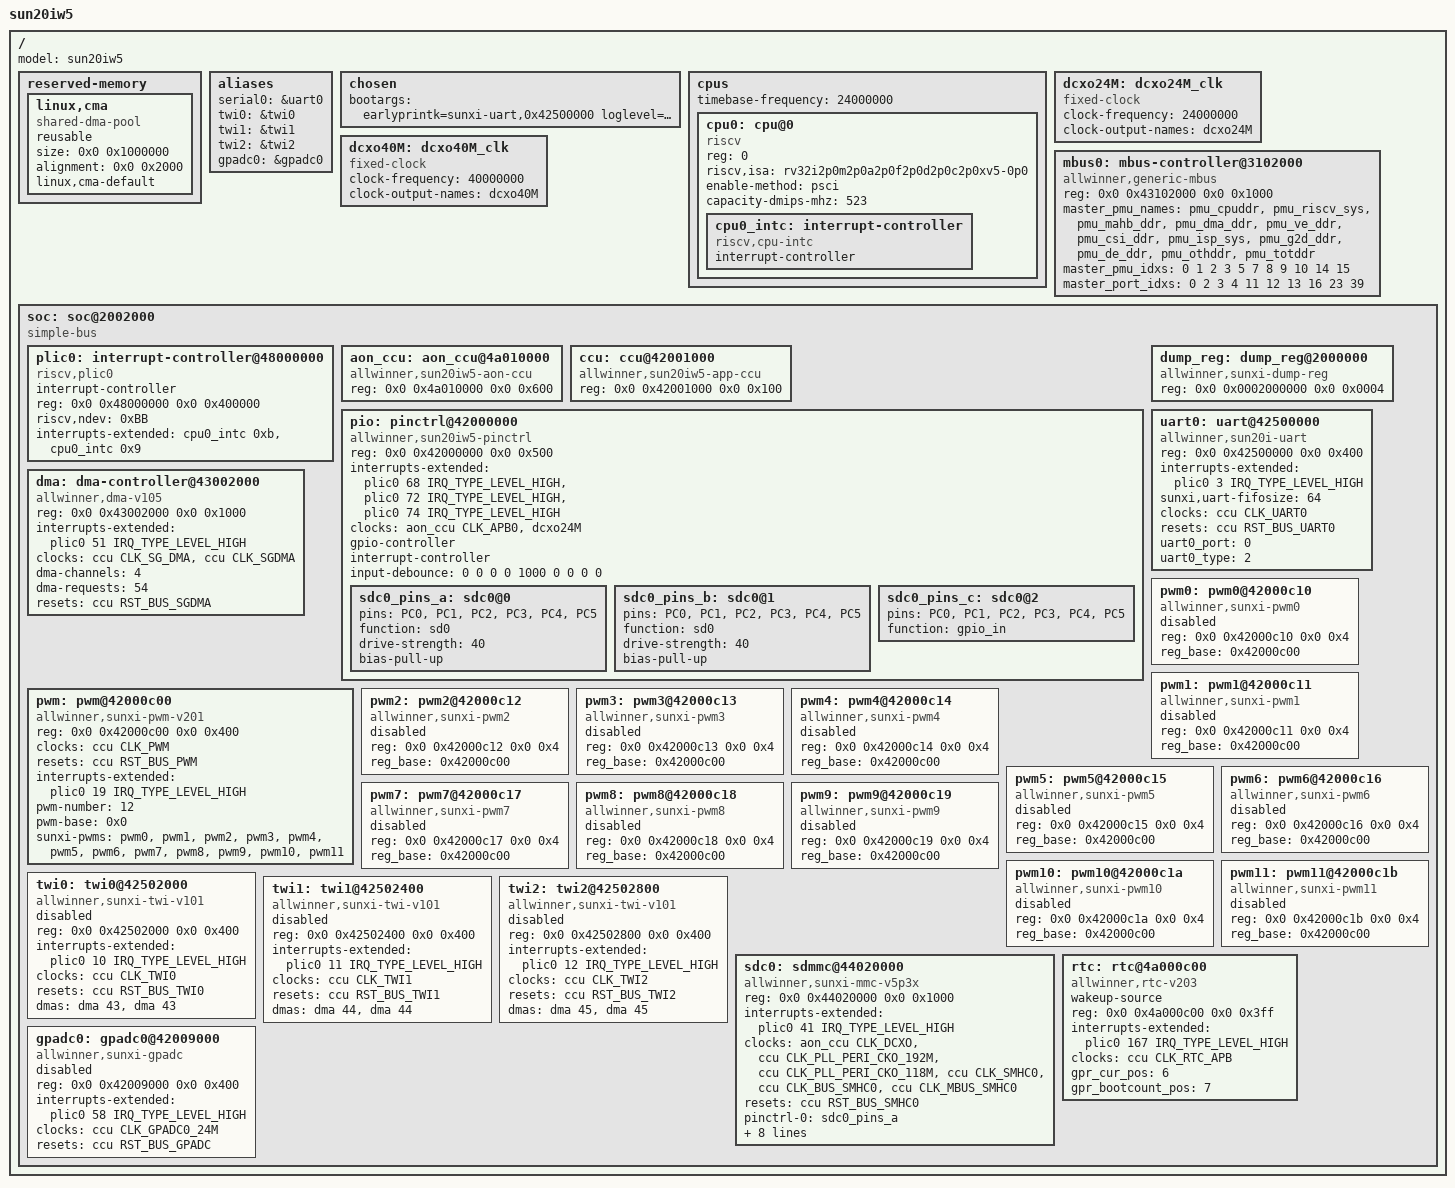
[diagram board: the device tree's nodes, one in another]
// SPDX-License-Identifier: (GPL-2.0+ or MIT)
/*
 * Copyright (C) 2023 rengaomin@allwinnertech.com
 */

/memreserve/ 0x84000000 0x100000; /* opensbi */

#include <dt-bindings/gpio/gpio.h>
#include <dt-bindings/gpio/sun4i-gpio.h>
#include <dt-bindings/thermal/thermal.h>
#include <dt-bindings/interrupt-controller/irq.h>
#include <dt-bindings/clock/sun20iw5-aon-ccu.h>
#include <dt-bindings/clock/sun20iw5-app-ccu.h>
#include <dt-bindings/reset/sun20iw5-app-ccu.h>

/ {
	model = "sun20iw5";
	#address-cells = <2>;
	#size-cells = <2>;

	reserved-memory {
		#address-cells = <2>;
		#size-cells = <2>;
		ranges;

		/* global autoconfigured region for contiguous allocations */
		linux,cma {
			compatible = "shared-dma-pool";
			reusable;
			size = <0x0 0x1000000>;
			alignment = <0x0 0x2000>;
			linux,cma-default;
		};

	};

	aliases {
		serial0 = &uart0;
		twi0 = &twi0;
		twi1 = &twi1;
		twi2 = &twi2;
		gpadc0 = &gpadc0;
	};

	chosen {
		bootargs = "earlyprintk=sunxi-uart,0x42500000 loglevel=8 initcall_debug=1 console=ttyAS0 init=/init";
	};

	cpus {
		#address-cells = <1>;
		#size-cells = <0>;
		timebase-frequency = <24000000>;

		cpu0: cpu@0 {
			device_type = "cpu";
			compatible = "riscv";
			reg = <0>;
			status = "okay";
			riscv,isa = "rv32i2p0m2p0a2p0f2p0d2p0c2p0xv5-0p0";
			enable-method = "psci";
			capacity-dmips-mhz = <523>;

			cpu0_intc: interrupt-controller {
				#interrupt-cells = <0x1>;
				interrupt-controller;
				compatible = "riscv,cpu-intc";
			};
		};
	};

	dcxo24M: dcxo24M_clk {
		#clock-cells = <0>;
		compatible = "fixed-clock";
		clock-frequency = <24000000>;
		clock-output-names = "dcxo24M";
	};

	dcxo40M: dcxo40M_clk {
		#clock-cells = <0>;
		compatible = "fixed-clock";
		clock-frequency = <40000000>;
		clock-output-names = "dcxo40M";
	};

	mbus0: mbus-controller@3102000 {
		compatible = "allwinner,generic-mbus";
		reg = <0x0 0x43102000 0x0 0x1000>;
		#mbus-cells = <1>;
		status = "okay";
		master_pmu_names = "pmu_cpuddr", "pmu_riscv_sys", "pmu_mahb_ddr",
		"pmu_dma_ddr", "pmu_ve_ddr", "pmu_csi_ddr", "pmu_isp_sys",
		"pmu_g2d_ddr", "pmu_de_ddr", "pmu_othddr", "pmu_totddr";
		master_pmu_idxs =<0 1 2 3 5 7 8 9 10 14 15>;
		master_port_idxs = <0 2 3 4 11 12 13 16 23 39>;
	};

	soc: soc@2002000 {
		compatible = "simple-bus";
		#address-cells = <2>;
		#size-cells = <2>;
		ranges;
		device_type = "soc";

		plic0: interrupt-controller@48000000 {
			compatible = "riscv,plic0";
			#address-cells = <0x2>;
			#interrupt-cells = <0x2>;
			interrupt-controller;
			reg = <0x0 0x48000000 0x0 0x400000>;
			riscv,ndev = <0xBB>;
			//interrupts-extended = <0x2 0xb 0x2 0x9>;
			interrupts-extended = <&cpu0_intc 0xb &cpu0_intc 0x9>;
		};

		aon_ccu: aon_ccu@4a010000{
			compatible = "allwinner,sun20iw5-aon-ccu";
			reg = <0x0 0x4a010000 0x0 0x600>;
			#clock-cells = <1>;
			#reset-cells = <1>;
		};

		ccu: ccu@42001000{
			compatible = "allwinner,sun20iw5-app-ccu";
			reg = <0x0 0x42001000 0x0 0x100>;
			#clock-cells = <1>;
			#reset-cells = <1>;
		};

		pio: pinctrl@42000000 {
			compatible = "allwinner,sun20iw5-pinctrl";
			reg = <0x0 0x42000000 0x0 0x500>;
			interrupts-extended = <&plic0 68 IRQ_TYPE_LEVEL_HIGH>,
				   <&plic0 72 IRQ_TYPE_LEVEL_HIGH>,
				   <&plic0 74 IRQ_TYPE_LEVEL_HIGH>;
			clocks = <&aon_ccu CLK_APB0>, <&dcxo24M>;
			clock-names = "apb", "hosc";
			device_type = "pio";
			gpio-controller;
			interrupt-controller;
			#interrupt-cells = <3>;
			#address-cells = <0>;
			#gpio-cells = <3>;
			input-debounce = <0 0 0 0 1000 0 0 0 0>;

			sdc0_pins_a: sdc0@0 {
				pins = "PC0", "PC1", "PC2",
						"PC3", "PC4", "PC5";
				function = "sd0";
				drive-strength = <40>;
				bias-pull-up;
			};

			sdc0_pins_b: sdc0@1 {
				pins = "PC0", "PC1", "PC2",
						"PC3", "PC4", "PC5";
				function = "sd0";
				drive-strength = <40>;
				bias-pull-up;
			};

			sdc0_pins_c: sdc0@2 {
				pins = "PC0", "PC1", "PC2",
						"PC3", "PC4", "PC5";
				function = "gpio_in";
			};
		};

		dump_reg:dump_reg@2000000 {
			compatible = "allwinner,sunxi-dump-reg";
			reg = <0x0 0x0002000000 0x0 0x0004>;
		};

		uart0: uart@42500000 {
			compatible = "allwinner,sun20i-uart";
			device_type = "uart0";
			reg = <0x0 0x42500000 0x0 0x400>;
			interrupts-extended = <&plic0 3 IRQ_TYPE_LEVEL_HIGH>;
			sunxi,uart-fifosize = <64>;
			clocks = <&ccu CLK_UART0>;
			resets = <&ccu RST_BUS_UART0>;
			uart0_port = <0>;
			uart0_type = <2>;
			status = "okay";
		};

		dma:dma-controller@43002000 {
			compatible = "allwinner,dma-v105";
			reg = <0x0 0x43002000 0x0 0x1000>;
			interrupts-extended = <&plic0 51 IRQ_TYPE_LEVEL_HIGH>;
			clocks = <&ccu CLK_SG_DMA>, <&ccu CLK_SGDMA>;
			clock-names = "bus", "mbus";
			dma-channels = <4>;
			dma-requests = <54>;
			resets = <&ccu RST_BUS_SGDMA>;
			#dma-cells = <1>;
			status = "okay";
		};

		pwm: pwm@42000c00 {
			#pwm-cells = <0x3>;
			compatible = "allwinner,sunxi-pwm-v201";
			reg = <0x0 0x42000c00 0x0 0x400>;
			clocks = <&ccu CLK_PWM>;
			resets = <&ccu RST_BUS_PWM>;
			interrupts-extended = <&plic0 19 IRQ_TYPE_LEVEL_HIGH>;
			pwm-number = <12>;
			pwm-base = <0x0>;
			sunxi-pwms = <&pwm0>, <&pwm1>, <&pwm2>, <&pwm3>, <&pwm4>,
					<&pwm5>, <&pwm6>, <&pwm7>, <&pwm8>,
					<&pwm9>, <&pwm10>, <&pwm11>;
			status = "okay";
		};

		pwm0: pwm0@42000c10 {
			compatible = "allwinner,sunxi-pwm0";
			pinctrl-names = "active", "sleep";
			reg = <0x0 0x42000c10 0x0 0x4>;
			reg_base = <0x42000c00>;
			status = "disabled";
		};

		pwm1: pwm1@42000c11 {
			compatible = "allwinner,sunxi-pwm1";
			pinctrl-names = "active", "sleep";
			reg = <0x0 0x42000c11 0x0 0x4>;
			reg_base = <0x42000c00>;
			status = "disabled";
		};

		pwm2: pwm2@42000c12 {
			compatible = "allwinner,sunxi-pwm2";
			pinctrl-names = "active", "sleep";
			reg = <0x0 0x42000c12 0x0 0x4>;
			reg_base = <0x42000c00>;
			status = "disabled";
		};

		pwm3: pwm3@42000c13 {
			compatible = "allwinner,sunxi-pwm3";
			pinctrl-names = "active", "sleep";
			reg = <0x0 0x42000c13 0x0 0x4>;
			reg_base = <0x42000c00>;
			status = "disabled";
		};

		pwm4: pwm4@42000c14 {
			compatible = "allwinner,sunxi-pwm4";
			pinctrl-names = "active", "sleep";
			reg = <0x0 0x42000c14 0x0 0x4>;
			reg_base = <0x42000c00>;
			status = "disabled";
		};

		pwm5: pwm5@42000c15 {
			compatible = "allwinner,sunxi-pwm5";
			pinctrl-names = "active", "sleep";
			reg = <0x0 0x42000c15 0x0 0x4>;
			reg_base = <0x42000c00>;
			status = "disabled";
		};

		pwm6: pwm6@42000c16 {
			compatible = "allwinner,sunxi-pwm6";
			pinctrl-names = "active", "sleep";
			reg = <0x0 0x42000c16 0x0 0x4>;
			reg_base = <0x42000c00>;
			status = "disabled";
		};

		pwm7: pwm7@42000c17 {
			compatible = "allwinner,sunxi-pwm7";
			pinctrl-names = "active", "sleep";
			reg = <0x0 0x42000c17 0x0 0x4>;
			reg_base = <0x42000c00>;
			status = "disabled";
		};

		pwm8: pwm8@42000c18 {
			compatible = "allwinner,sunxi-pwm8";
			pinctrl-names = "active", "sleep";
			reg = <0x0 0x42000c18 0x0 0x4>;
			reg_base = <0x42000c00>;
			status = "disabled";
		};

		pwm9: pwm9@42000c19 {
			compatible = "allwinner,sunxi-pwm9";
			pinctrl-names = "active", "sleep";
			reg = <0x0 0x42000c19 0x0 0x4>;
			reg_base = <0x42000c00>;
			status = "disabled";
		};

		pwm10: pwm10@42000c1a {
			compatible = "allwinner,sunxi-pwm10";
			pinctrl-names = "active", "sleep";
			reg = <0x0 0x42000c1a 0x0 0x4>;
			reg_base = <0x42000c00>;
			status = "disabled";
		};

		pwm11: pwm11@42000c1b {
			compatible = "allwinner,sunxi-pwm11";
			pinctrl-names = "active", "sleep";
			reg = <0x0 0x42000c1b 0x0 0x4>;
			reg_base = <0x42000c00>;
			status = "disabled";
		};

		twi0: twi0@42502000 {
			compatible = "allwinner,sunxi-twi-v101";
			device_type = "twi0";
			reg = <0x0 0x42502000 0x0 0x400>;
			interrupts-extended = <&plic0 10 IRQ_TYPE_LEVEL_HIGH>;
			clocks = <&ccu CLK_TWI0>;
			clock-names = "bus";
			resets = <&ccu RST_BUS_TWI0>;
			dmas = <&dma 43>, <&dma 43>;
			dma-names = "tx", "rx";
			status = "disabled";
		};

		twi1: twi1@42502400 {
			compatible = "allwinner,sunxi-twi-v101";
			device_type = "twi1";
			reg = <0x0 0x42502400 0x0 0x400>;
			interrupts-extended = <&plic0 11 IRQ_TYPE_LEVEL_HIGH>;
			clocks = <&ccu CLK_TWI1>;
			clock-names = "bus";
			resets = <&ccu RST_BUS_TWI1>;
			dmas = <&dma 44>, <&dma 44>;
			dma-names = "tx", "rx";
			status = "disabled";
		};

		twi2: twi2@42502800 {
			compatible = "allwinner,sunxi-twi-v101";
			device_type = "twi2";
			reg = <0x0 0x42502800 0x0 0x400>;
			interrupts-extended = <&plic0 12 IRQ_TYPE_LEVEL_HIGH>;
			clocks = <&ccu CLK_TWI2>;
			clock-names = "bus";
			resets = <&ccu RST_BUS_TWI2>;
			dmas = <&dma 45>, <&dma 45>;
			dma-names = "tx", "rx";
			status = "disabled";
		};

		sdc0: sdmmc@44020000 {
			compatible = "allwinner,sunxi-mmc-v5p3x";
			device_type = "sdc0";
			reg = <0x0 0x44020000 0x0 0x1000>;
			interrupts-extended = <&plic0 41 IRQ_TYPE_LEVEL_HIGH>;
			clocks = <&aon_ccu CLK_DCXO>,
				<&ccu CLK_PLL_PERI_CKO_192M>,
				<&ccu CLK_PLL_PERI_CKO_118M>,
				<&ccu CLK_SMHC0>,
				<&ccu CLK_BUS_SMHC0>,
				<&ccu CLK_MBUS_SMHC0>;
			clock-names = "osc24m","pll_periph","pll_periph_2","mmc","ahb","mbus";
			resets = <&ccu RST_BUS_SMHC0>;
			reset-names = "rst";
			pinctrl-names = "default","mmc_1v8","sleep";
			pinctrl-0 = <&sdc0_pins_a>;
			pinctrl-1 = <&sdc0_pins_b>;
			pinctrl-2 = <&sdc0_pins_c>;
			/*pinctrl-3 = <&sdc0_pins_d &sdc0_pins_e>;*/
			max-frequency = <50000000>;
			bus-width = <4>;
			req-page-count = <2>;
			/*non-removable;*/
			/*broken-cd;*/
			/*cd-inverted*/
			/*cd-gpios = <&pio PF 6 GPIO_ACTIVE_LOW>;*/
			/* vmmc-supply = <&reg_3p3v>;*/
			/* vqmc-supply = <&reg_3p3v>;*/
			/* vdmc-supply = <&reg_3p3v>;*/
			/*vmmc = "vcc-card";*/
			/*vqmc = "";*/
			/*vdmc = "";*/
			cap-sd-highspeed;
			cap-wait-while-busy;
			/*sd-uhs-sdr50;*/
			/*sd-uhs-ddr50;*/
			/*cap-sdio-irq;*/
			/*keep-power-in-suspend;*/
			/*ignore-pm-notify;*/
			/*sunxi-power-save-mode;*/
			/*sunxi-dly-400k = <1 0 0 0>; */
			/*sunxi-dly-26M  = <1 0 0 0>;*/
			/*sunxi-dly-52M  = <1 0 0 0>;*/
			/*sunxi-dly-52M-ddr4  = <1 0 0 0>;*/
			/*sunxi-dly-52M-ddr8  = <1 0 0 0>;*/
			/*sunxi-dly-104M  = <1 0 0 0>;*/
			/*sunxi-dly-208M  = <1 0 0 0>;*/
			/*sunxi-dly-104M-ddr  = <1 0 0 0>;*/
			/*sunxi-dly-208M-ddr  = <1 0 0 0>;*/
			ctl-spec-caps = <0x428>;
			status = "okay";
		};

		rtc: rtc@4a000c00 {
			compatible = "allwinner,rtc-v203";
			device_type = "rtc";
			wakeup-source;
			reg = <0x0 0x4a000c00 0x0 0x3ff>;
			interrupts-extended = <&plic0 167 IRQ_TYPE_LEVEL_HIGH>;
			clocks = <&ccu CLK_RTC_APB>;
			clock-names = "r-ahb-rtc";
			gpr_cur_pos = <6>;
			gpr_bootcount_pos = <7>;
		};

		gpadc0: gpadc0@42009000 {
			compatible = "allwinner,sunxi-gpadc";
			reg = <0x0 0x42009000 0x0 0x400>;
			interrupts-extended = <&plic0 58 IRQ_TYPE_LEVEL_HIGH>;
			clocks = <&ccu CLK_GPADC0_24M>;
			clock-names = "bus";
			resets = <&ccu RST_BUS_GPADC>;
			status = "disabled";
		};
	};
};
